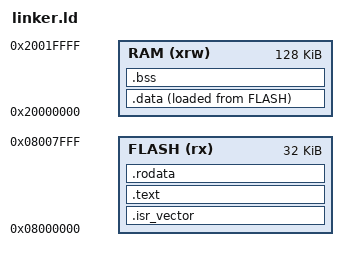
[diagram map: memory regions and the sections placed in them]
MEMORY
{
    /*
     * Sector 0 = 16 KB
     * Sector 1 = 16 KB
     * Total bootloader space = 32 KB
     */

    /* Bootloader starts at beginning of Flash and occupies 2 sectors */

    /* Flash mode -> read and execute */
    FLASH (rx) : ORIGIN = 0x08000000, LENGTH = 32K


    /*
     * SRAM1 = 112 KB
     * SRAM2 = 16 KB
     * Total = 128 KB
     */

    /* RAM used for runtime data such as .data and .bss */

    /* Bootloader and application do not run simultaneously */

    /* RAM mode -> read, write and execute */
    RAM (xrw) : ORIGIN = 0x20000000, LENGTH = 128K
}


/* _estack is the initial stack pointer value,
 * located at the top/end of the RAM address space */
_estack = ORIGIN(RAM) + LENGTH(RAM);


SECTIONS
{
    /*
     * The vector table is placed at the beginning of the Flash memory
     */
    
    .isr_vector :
    {
        /*
         * Keep the interrupt vector table at the beginning of Flash.
         * KEEP() prevents the linker from discarding the section
         * even if it appears to be unused.
         */
        . = ALIGN(128);

        KEEP(*(.isr_vector))

        . = ALIGN(128);
        
    } > FLASH


    /*
     * The .text section contains the executable code of the program.
     * .text.* stores the subsections of the .text section,
     * which can be generated by the compiler.
     */
    .text :
    {
        *(.text)
        *(.text.*)
    } > FLASH


    /*
     * The .rodata section contains read-only data of the program.
     * .rodata.* stores the subsections of the .rodata section.
     *
     * Example: const variables, string literals, etc.
     */
    .rodata :
    {
        *(.rodata)
        *(.rodata.*)
    } > FLASH


    /*
     * _sidata stores the Flash address of the initial values
     * of the .data section.
     *
     * These values will be copied from Flash to RAM during startup.
     */
    _sidata = LOADADDR(.data);


    /*
     * The .data section contains initialized data of the program.
     * .data.* stores the subsections of the .data section.
     *
     * The actual variables are located in RAM at runtime,
     * while their initial values are stored in Flash.
     *
     * > RAM      -> runtime location of .data
     * AT > FLASH -> location of the initial values in Flash
     */


     
    .data :
    {
        /* Start address of .data in RAM */
        _sdata = .;

        *(.data)
        *(.data.*)

        /* End address of .data in RAM */
        _edata = .;
    } > RAM AT > FLASH


    /*
     * The .bss section contains uninitialized data of the program.
     * .bss.* stores the subsections of the .bss section.
     *
     * These variables are placed in RAM and are initialized to zero
     * by the startup code before main() is called.
     *
     * COMMON is a special section that can contain uninitialized
     * global data shared between multiple source files.
     */
    .bss :
    {
        /* Start address of .bss in RAM */
        _sbss = .;

        *(.bss)
        *(.bss.*)
        *(COMMON)

        /* End address of .bss in RAM */
        _ebss = .;
    } > RAM


    /*
     * Align the next address to an 8-byte boundary.
     */
    . = ALIGN(8);

    /*
     * _end marks the end of the data sections in RAM.
     */
    _end = .;
}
